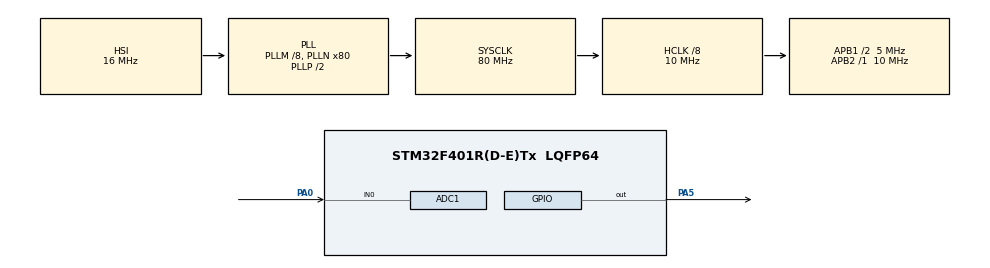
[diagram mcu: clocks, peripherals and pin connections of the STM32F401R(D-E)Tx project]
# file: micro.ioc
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ADC1.Channel-0\#ChannelRegularConversion=ADC_CHANNEL_0
ADC1.NbrOfConversionFlag=1
ADC1.Rank-0\#ChannelRegularConversion=1
ADC1.SamplingTime-0\#ChannelRegularConversion=ADC_SAMPLETIME_3CYCLES
ADC1.master=1
Mcu.Family=STM32F4
Mcu.Name=STM32F401R(D-E)Tx
Mcu.Package=LQFP64
NVIC.PriorityGroup=NVIC_PRIORITYGROUP_0
NVIC.TIM1_UP_TIM10_IRQn=true\:0\:0\:false\:false\:true\:true\:true
NVIC.TIM2_IRQn=true\:0\:0\:false\:false\:true\:true\:true
PA0-WKUP.Signal=ADCx_IN0
PA5.Signal=GPIO_Output
PH0\ -\ OSC_IN.Mode=HSE-External-Oscillator
PH0\ -\ OSC_IN.Signal=RCC_OSC_IN
PH1\ -\ OSC_OUT.Mode=HSE-External-Oscillator
PH1\ -\ OSC_OUT.Signal=RCC_OSC_OUT
ProjectManager.HeapSize=0x200
ProjectManager.StackSize=0x400
ProjectManager.TargetToolchain=EWARM V8
RCC.48MHZClocksFreq_Value=22857142.85714286
RCC.AHBCLKDivider=RCC_SYSCLK_DIV8
RCC.AHBFreq_Value=10000000
RCC.APB1CLKDivider=RCC_HCLK_DIV2
RCC.APB1Freq_Value=5000000
RCC.APB1TimFreq_Value=10000000
RCC.APB2Freq_Value=10000000
RCC.APB2TimFreq_Value=10000000
RCC.CortexFreq_Value=10000000
RCC.HCLKFreq_Value=10000000
RCC.HSE_VALUE=8000000
RCC.HSI_VALUE=16000000
RCC.LSE_VALUE=32768
RCC.PLLM=8
RCC.PLLN=80
RCC.PLLQ=7
RCC.SYSCLKFreq_VALUE=80000000
RCC.SYSCLKSource=RCC_SYSCLKSOURCE_PLLCLK
RCC.VCOOutputFreq_Value=160000000
SH.ADCx_IN0.0=ADC1_IN0,IN0
TIM1.Period=9999
TIM1.Prescaler=49999
TIM2.Period=1999
TIM2.Prescaler=4999
VP_TIM1_VS_ClockSourceINT.Mode=Internal
VP_TIM2_VS_ClockSourceINT.Mode=Internal
board=NUCLEO-F401RE

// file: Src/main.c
/* USER CODE BEGIN Header */
/**
  ******************************************************************************
  * @file           : main.c
  * @brief          : Main program body
  ******************************************************************************
  * @attention
  *
  * <h2><center>&copy; Copyright (c) 2019 STMicroelectronics.
  * All rights reserved.</center></h2>
  *
  * This software component is licensed by ST under BSD 3-Clause license,
  * the "License"; You may not use this file except in compliance with the
  * License. You may obtain a copy of the License at:
  *                        opensource.org/licenses/BSD-3-Clause
  *
  ******************************************************************************
  */
/* USER CODE END Header */

#include "main.h"

/* USER CODE BEGIN PD */

//Set thresholds [mV]
#define S1 1100
#define S2 2200

/* USER CODE END PD */

ADC_HandleTypeDef hadc1;

TIM_HandleTypeDef htim1;
TIM_HandleTypeDef htim2;

/* USER CODE BEGIN PV */

uint32_t rawValue = 0;          //raw value from ADC conversion
float value = 0;                //converted raw value
uint8_t state = 0;              //variable to check if the system is in the slowly variable state

/* USER CODE END PV */

void SystemClock_Config(void);
static void MX_GPIO_Init(void);
static void MX_ADC1_Init(void);
static void MX_TIM1_Init(void);
static void MX_TIM2_Init(void);
/* USER CODE BEGIN PFP */

//Get TIM seconds
float Get_TIM_Seconds(TIM_HandleTypeDef *htim);

/* USER CODE END PFP */

int main(void)
{

  /* MCU Configuration--------------------------------------------------------*/

  /* Reset of all peripherals, Initializes the Flash interface and the Systick. */
  HAL_Init();

  /* Configure the system clock */
  SystemClock_Config();

  /* Initialize all configured peripherals */
  MX_GPIO_Init();
  MX_ADC1_Init();
  MX_TIM1_Init();
  MX_TIM2_Init();

  /* Infinite loop */
  /* USER CODE BEGIN WHILE */
  while (1)
  {

    HAL_ADC_Start(&hadc1);      //Start ADC
    HAL_ADC_PollForConversion(&hadc1, HAL_MAX_DELAY);   //Waiting for end of conversion
    rawValue = HAL_ADC_GetValue(&hadc1);        //Read ADC converted value
    HAL_ADC_Stop(&hadc1);       //Stop ADC

    value = ((float) rawValue) / 4096 * 3300;   //Convert rawValue in mV

    if (value < S1) {

      //LED blinking at 0.5 Hz
      htim2.Instance->ARR = 1999;       //Set (period + 1) = 2000;
      HAL_TIM_Base_Start_IT(&htim2);    //Start TIM2 in interrupt mode

      //Clear TIM1 Update Flag to avoid immediatly calling IRQ handle function
      __HAL_TIM_CLEAR_FLAG(&htim1, TIM_FLAG_UPDATE);
      htim1.Instance->CNT = 0;          //Set TIM1 Counter Register equal to 0
      HAL_TIM_Base_Start_IT(&htim1);    //Start TIM1 in interrupt mode
      state = 0;        //System out of the slowly variable state

    } else if (value > S2) {

      if ((Get_TIM_Seconds(&htim1) < 5) && !state) {

        //LED blinking at 1 Hz
        htim2.Instance->ARR = 999;       //Set (period + 1) = 1000;
        HAL_TIM_Base_Start_IT(&htim2);    //Start TIM2 in interrupt mode
        HAL_TIM_Base_Stop_IT(&htim1);    //Stop TIM1 in interrupt mode
        htim1.Instance->CNT = 0;          //Set TIM1 Counter Register equal to 0

      } else {

        HAL_TIM_Base_Stop_IT(&htim1);    //Stop TIM1 in interrupt mode
        htim1.Instance->CNT = 0;          //Set TIM1 Counter Register equal to 0
        HAL_TIM_Base_Stop_IT(&htim2);    //Stop TIM2 in interrupt mode
        HAL_GPIO_WritePin(GPIOA, GPIO_PIN_5, GPIO_PIN_SET);     //LED ON
        state = 1;              //System in the slowly variable state

      }

    } else {

      HAL_TIM_Base_Stop_IT(&htim2);    //Stop TIM2 in interrupt mode
      HAL_GPIO_WritePin(GPIOA, GPIO_PIN_5, GPIO_PIN_RESET);     //LED OFF
      state = 0;        //System out of the slowly variable state

    }

    HAL_Delay(1000);     //Wait 1s before the next cycle

    /* USER CODE END WHILE */

  }
}

void SystemClock_Config(void)
{
  RCC_OscInitTypeDef RCC_OscInitStruct = {0};
  RCC_ClkInitTypeDef RCC_ClkInitStruct = {0};

  /** Configure the main internal regulator output voltage
  */
  __HAL_RCC_PWR_CLK_ENABLE();
  __HAL_PWR_VOLTAGESCALING_CONFIG(PWR_REGULATOR_VOLTAGE_SCALE2);
  /** Initializes the CPU, AHB and APB busses clocks
  */
  RCC_OscInitStruct.OscillatorType = RCC_OSCILLATORTYPE_HSI;
  RCC_OscInitStruct.HSIState = RCC_HSI_ON;
  RCC_OscInitStruct.HSICalibrationValue = RCC_HSICALIBRATION_DEFAULT;
  RCC_OscInitStruct.PLL.PLLState = RCC_PLL_ON;
  RCC_OscInitStruct.PLL.PLLSource = RCC_PLLSOURCE_HSI;
  RCC_OscInitStruct.PLL.PLLM = 8;
  RCC_OscInitStruct.PLL.PLLN = 80;
  RCC_OscInitStruct.PLL.PLLP = RCC_PLLP_DIV2;
  RCC_OscInitStruct.PLL.PLLQ = 7;
  if (HAL_RCC_OscConfig(&RCC_OscInitStruct) != HAL_OK)
  {
    Error_Handler();
  }
  /** Initializes the CPU, AHB and APB busses clocks
  */
  RCC_ClkInitStruct.ClockType = RCC_CLOCKTYPE_HCLK|RCC_CLOCKTYPE_SYSCLK
                              |RCC_CLOCKTYPE_PCLK1|RCC_CLOCKTYPE_PCLK2;
  RCC_ClkInitStruct.SYSCLKSource = RCC_SYSCLKSOURCE_PLLCLK;
  RCC_ClkInitStruct.AHBCLKDivider = RCC_SYSCLK_DIV8;
  RCC_ClkInitStruct.APB1CLKDivider = RCC_HCLK_DIV2;
  RCC_ClkInitStruct.APB2CLKDivider = RCC_HCLK_DIV1;

  if (HAL_RCC_ClockConfig(&RCC_ClkInitStruct, FLASH_LATENCY_0) != HAL_OK)
  {
    Error_Handler();
  }
}

static void MX_ADC1_Init(void)
{

  ADC_ChannelConfTypeDef sConfig = {0};

  /** Configure the global features of the ADC (Clock, Resolution, Data Alignment and number of conversion)
  */
  hadc1.Instance = ADC1;
  hadc1.Init.ClockPrescaler = ADC_CLOCK_SYNC_PCLK_DIV2;
  hadc1.Init.Resolution = ADC_RESOLUTION_12B;
  hadc1.Init.ScanConvMode = DISABLE;
  hadc1.Init.ContinuousConvMode = DISABLE;
  hadc1.Init.DiscontinuousConvMode = DISABLE;
  hadc1.Init.ExternalTrigConvEdge = ADC_EXTERNALTRIGCONVEDGE_NONE;
  hadc1.Init.ExternalTrigConv = ADC_SOFTWARE_START;
  hadc1.Init.DataAlign = ADC_DATAALIGN_RIGHT;
  hadc1.Init.NbrOfConversion = 1;
  hadc1.Init.DMAContinuousRequests = DISABLE;
  hadc1.Init.EOCSelection = ADC_EOC_SINGLE_CONV;
  if (HAL_ADC_Init(&hadc1) != HAL_OK)
  {
    Error_Handler();
  }
  /** Configure for the selected ADC regular channel its corresponding rank in the sequencer and its sample time.
  */
  sConfig.Channel = ADC_CHANNEL_0;
  sConfig.Rank = 1;
  sConfig.SamplingTime = ADC_SAMPLETIME_3CYCLES;
  if (HAL_ADC_ConfigChannel(&hadc1, &sConfig) != HAL_OK)
  {
    Error_Handler();
  }

}

static void MX_TIM1_Init(void)
{

  TIM_ClockConfigTypeDef sClockSourceConfig = {0};
  TIM_MasterConfigTypeDef sMasterConfig = {0};

  htim1.Instance = TIM1;
  htim1.Init.Prescaler = 49999;
  htim1.Init.CounterMode = TIM_COUNTERMODE_UP;
  htim1.Init.Period = 9999;
  htim1.Init.ClockDivision = TIM_CLOCKDIVISION_DIV1;
  htim1.Init.RepetitionCounter = 0;
  htim1.Init.AutoReloadPreload = TIM_AUTORELOAD_PRELOAD_DISABLE;
  if (HAL_TIM_Base_Init(&htim1) != HAL_OK)
  {
    Error_Handler();
  }
  sClockSourceConfig.ClockSource = TIM_CLOCKSOURCE_INTERNAL;
  if (HAL_TIM_ConfigClockSource(&htim1, &sClockSourceConfig) != HAL_OK)
  {
    Error_Handler();
  }
  sMasterConfig.MasterOutputTrigger = TIM_TRGO_RESET;
  sMasterConfig.MasterSlaveMode = TIM_MASTERSLAVEMODE_DISABLE;
  if (HAL_TIMEx_MasterConfigSynchronization(&htim1, &sMasterConfig) != HAL_OK)
  {
    Error_Handler();
  }

}

static void MX_TIM2_Init(void)
{

  TIM_ClockConfigTypeDef sClockSourceConfig = {0};
  TIM_MasterConfigTypeDef sMasterConfig = {0};

  htim2.Instance = TIM2;
  htim2.Init.Prescaler = 4999;
  htim2.Init.CounterMode = TIM_COUNTERMODE_UP;
  htim2.Init.Period = 1999;
  htim2.Init.ClockDivision = TIM_CLOCKDIVISION_DIV1;
  htim2.Init.AutoReloadPreload = TIM_AUTORELOAD_PRELOAD_DISABLE;
  if (HAL_TIM_Base_Init(&htim2) != HAL_OK)
  {
    Error_Handler();
  }
  sClockSourceConfig.ClockSource = TIM_CLOCKSOURCE_INTERNAL;
  if (HAL_TIM_ConfigClockSource(&htim2, &sClockSourceConfig) != HAL_OK)
  {
    Error_Handler();
  }
  sMasterConfig.MasterOutputTrigger = TIM_TRGO_RESET;
  sMasterConfig.MasterSlaveMode = TIM_MASTERSLAVEMODE_DISABLE;
  if (HAL_TIMEx_MasterConfigSynchronization(&htim2, &sMasterConfig) != HAL_OK)
  {
    Error_Handler();
  }

}

static void MX_GPIO_Init(void)
{
  GPIO_InitTypeDef GPIO_InitStruct = {0};

  /* GPIO Ports Clock Enable */
  __HAL_RCC_GPIOH_CLK_ENABLE();
  __HAL_RCC_GPIOA_CLK_ENABLE();

  /*Configure GPIO pin Output Level */
  HAL_GPIO_WritePin(GPIOA, GPIO_PIN_5, GPIO_PIN_RESET);

  /*Configure GPIO pin : PA5 */
  GPIO_InitStruct.Pin = GPIO_PIN_5;
  GPIO_InitStruct.Mode = GPIO_MODE_OUTPUT_PP;
  GPIO_InitStruct.Pull = GPIO_NOPULL;
  GPIO_InitStruct.Speed = GPIO_SPEED_FREQ_LOW;
  HAL_GPIO_Init(GPIOA, &GPIO_InitStruct);

}

/* USER CODE BEGIN 4 */
float Get_TIM_Seconds(TIM_HandleTypeDef *htim) {
  int tim_value = htim->Instance->CNT;
  tim_value *= (htim->Instance->PSC + 1);
  return ((float) (tim_value))/ 10000000;
}
/* USER CODE END 4 */

void Error_Handler(void)
{
}

/************************ (C) COPYRIGHT STMicroelectronics *****END OF FILE****/
